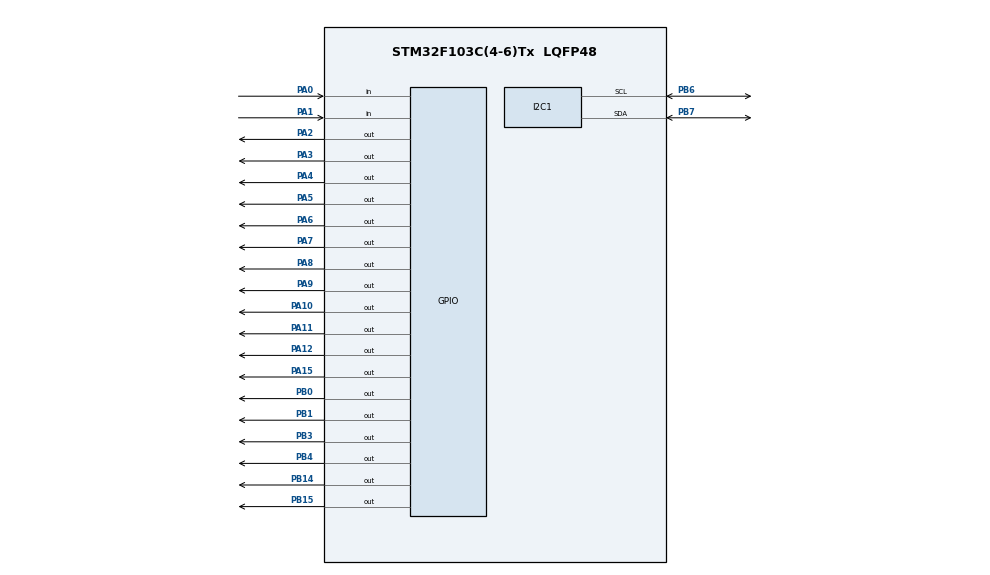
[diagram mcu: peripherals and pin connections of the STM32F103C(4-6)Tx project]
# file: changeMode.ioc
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Mcu.Family=STM32F1
Mcu.Name=STM32F103C(4-6)Tx
Mcu.Package=LQFP48
NVIC.PriorityGroup=NVIC_PRIORITYGROUP_4
PA0-WKUP.GPIO_PuPd=GPIO_PULLUP
PA0-WKUP.Signal=GPIO_Input
PA1.GPIO_PuPd=GPIO_PULLUP
PA1.Signal=GPIO_Input
PA10.Signal=GPIO_Output
PA11.Signal=GPIO_Output
PA12.Signal=GPIO_Output
PA13.Mode=Serial_Wire
PA13.Signal=SYS_JTMS-SWDIO
PA14.Mode=Serial_Wire
PA14.Signal=SYS_JTCK-SWCLK
PA15.Signal=GPIO_Output
PA2.Signal=GPIO_Output
PA3.Signal=GPIO_Output
PA4.Signal=GPIO_Output
PA5.Signal=GPIO_Output
PA6.Signal=GPIO_Output
PA7.Signal=GPIO_Output
PA8.Signal=GPIO_Output
PA9.Signal=GPIO_Output
PB0.Signal=GPIO_Output
PB1.Signal=GPIO_Output
PB14.Signal=GPIO_Output
PB15.Signal=GPIO_Output
PB3.Signal=GPIO_Output
PB4.Signal=GPIO_Output
PB6.Mode=I2C
PB6.Signal=I2C1_SCL
PB7.Mode=I2C
PB7.Signal=I2C1_SDA
PD0-OSC_IN.Mode=HSE-External-Oscillator
PD0-OSC_IN.Signal=RCC_OSC_IN
PD1-OSC_OUT.Mode=HSE-External-Oscillator
PD1-OSC_OUT.Signal=RCC_OSC_OUT
ProjectManager.HeapSize=0x200
ProjectManager.StackSize=0x400
ProjectManager.TargetToolchain=MDK-ARM V5
RCC.APB1Freq_Value=8000000
RCC.APB2Freq_Value=8000000
board=custom

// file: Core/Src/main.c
/* USER CODE BEGIN Header */
/**
  ******************************************************************************
  * @file           : main.c
  * @brief          : Main program body
  ******************************************************************************
  * @attention
  *
  * Copyright (c) 2024 STMicroelectronics.
  * All rights reserved.
  *
  * This software is licensed under terms that can be found in the LICENSE file
  * in the root directory of this software component.
  * If no LICENSE file comes with this software, it is provided AS-IS.
  *
  ******************************************************************************
  */
/* USER CODE END Header */
#include "main.h"
#include "lcd.h"
#include "stdio.h"

I2C_HandleTypeDef hi2c1;

void SystemClock_Config(void);
static void MX_GPIO_Init(void);
static void MX_I2C1_Init(void);

/* USER CODE BEGIN 0 */
void display7Seg(int data);
//void HAL_GPIO_EXTI_Callback(uint16_t GPIO_Pin);
//void show_traffic(uint8_t BacK_Green1, uint8_t BacK_Yellow1,
//	uint8_t BacK_Green2, uint8_t BacK_Yellow2);
//void sleep();
int status;
int counter1;
int counter2;
enum ledColor{
	GREEN,
	YELLOW,
	RED
};
//void sleep(){
////	if(status == 0)
////	{
//	HAL_GPIO_WritePin(GPIOB, GPIO_PIN_15, GPIO_PIN_RESET);
//	HAL_GPIO_WritePin(GPIOB, GPIO_PIN_14, GPIO_PIN_RESET);
//	HAL_GPIO_WritePin(GPIOB, GPIO_PIN_1, GPIO_PIN_RESET);
//	HAL_GPIO_WritePin(GPIOB, GPIO_PIN_0, GPIO_PIN_RESET);
//	while(1){
//
//	//led yellow blink 1HZ
//	HAL_GPIO_WritePin(GPIOA, GPIO_PIN_7, GPIO_PIN_RESET);//R1
//	HAL_GPIO_WritePin(GPIOA, GPIO_PIN_6, GPIO_PIN_RESET);//Y1
//	HAL_GPIO_WritePin(GPIOA, GPIO_PIN_5, GPIO_PIN_RESET);//G1
//	HAL_GPIO_WritePin(GPIOA, GPIO_PIN_4, GPIO_PIN_RESET);//R2
//	HAL_GPIO_WritePin(GPIOA, GPIO_PIN_3, GPIO_PIN_RESET);//Y2
//	HAL_GPIO_WritePin(GPIOA, GPIO_PIN_2, GPIO_PIN_RESET);//G2
//	HAL_Delay(500);
//	HAL_GPIO_WritePin(GPIOA, GPIO_PIN_6, GPIO_PIN_SET);//Y1
//	HAL_GPIO_WritePin(GPIOA, GPIO_PIN_3, GPIO_PIN_SET);//Y2
//	HAL_Delay(500);
//	if(HAL_GPIO_ReadPin(GPIOA, GPIO_PIN_1) == 0){
//		//while(HAL_GPIO_ReadPin(GPIOA, GPIO_PIN_1) == 1);
//		break;
//		status = 0;
//	}

//	}

//}

//void show_traffic(uint8_t BacK_Green1, uint8_t BacK_Yellow1,
//	uint8_t BacK_Green2, uint8_t BacK_Yellow2){
//
//	uint8_t c_Green1 = BacK_Green1;
//	uint8_t c_Yellow1 = BacK_Yellow1;
//	uint8_t c_Red1 = BacK_Green1 + BacK_Yellow1;
//	uint8_t BacK_Red1 = c_Red1;
//	enum ledColor cur_color1 = GREEN;
//
//	uint8_t c_Green2 = BacK_Green2;
//	uint8_t c_Yellow2 = BacK_Yellow2;
//	uint8_t c_Red2 = BacK_Green2 + BacK_Yellow2;
//	uint8_t BacK_Red2 = c_Red2;
//	enum ledColor cur_color2 = RED;
//
//	uint8_t c_1s = BacK_Green1 + BacK_Red2 + 2;
//
//	counter1 = BacK_Green1 - 1;
//	counter2 = BacK_Red2 - 1;
//
//	int sw_led = 0;
//
//	HAL_GPIO_WritePin(GPIOA, GPIO_PIN_7, GPIO_PIN_RESET);//R1
//	HAL_GPIO_WritePin(GPIOA, GPIO_PIN_5, GPIO_PIN_SET);//G1
//	HAL_GPIO_WritePin(GPIOA, GPIO_PIN_6, GPIO_PIN_RESET);//Y1
//
//	HAL_GPIO_WritePin(GPIOA, GPIO_PIN_4, GPIO_PIN_SET);//R2
//	HAL_GPIO_WritePin(GPIOA, GPIO_PIN_2, GPIO_PIN_RESET);//G2
//	HAL_GPIO_WritePin(GPIOA, GPIO_PIN_3, GPIO_PIN_RESET);//Y2
//
////	Lcd_Write_Command(0x80);//write first line 1
////	Lcd_Write_String("Mode:");
////	Lcd_Write_Command(0xC0);//write first line 2
////	Lcd_Write_String("Binh Thuong.");
//
//	while(1){
//		//if(*sleep_mode == 22) break;
//		if(c_Green1 <= 0){
//			HAL_GPIO_WritePin(GPIOA, GPIO_PIN_7, GPIO_PIN_RESET);
//			HAL_GPIO_WritePin(GPIOA, GPIO_PIN_5, GPIO_PIN_RESET);
//			HAL_GPIO_WritePin(GPIOA, GPIO_PIN_6, GPIO_PIN_SET);
//			c_Green1 = BacK_Green1;
//			cur_color1 = YELLOW;
//			counter1 = BacK_Yellow1 - 1;
//		}
//		if(c_Yellow1 <= 0){
//			HAL_GPIO_WritePin(GPIOA, GPIO_PIN_7, GPIO_PIN_SET);
//			HAL_GPIO_WritePin(GPIOA, GPIO_PIN_5, GPIO_PIN_RESET);
//			HAL_GPIO_WritePin(GPIOA, GPIO_PIN_6, GPIO_PIN_RESET);
//			c_Yellow1 = BacK_Yellow1;
//			cur_color1 = RED;
//			counter1 = BacK_Red1 - 1;
//		}

//		if(c_Red1 <= 0){
//			HAL_GPIO_WritePin(GPIOA, GPIO_PIN_7, GPIO_PIN_RESET);
//			HAL_GPIO_WritePin(GPIOA, GPIO_PIN_5, GPIO_PIN_SET);
//			HAL_GPIO_WritePin(GPIOA, GPIO_PIN_6, GPIO_PIN_RESET);
//			c_Red1 = BacK_Green1 + BacK_Yellow1;
//			cur_color1 = GREEN;
//			counter1 = BacK_Green1 - 1;
//		}
//		if(c_Green2 <= 0){
//			HAL_GPIO_WritePin(GPIOA, GPIO_PIN_4, GPIO_PIN_RESET);
//			HAL_GPIO_WritePin(GPIOA, GPIO_PIN_2, GPIO_PIN_RESET);
//			HAL_GPIO_WritePin(GPIOA, GPIO_PIN_3, GPIO_PIN_SET);
//			c_Green2 = BacK_Green2 - 1;
//			cur_color2 = YELLOW;
//			counter2 = BacK_Yellow2 - 1;
//		}
//		if(c_Yellow2 <= 0){
//			HAL_GPIO_WritePin(GPIOA, GPIO_PIN_4, GPIO_PIN_SET);
//			HAL_GPIO_WritePin(GPIOA, GPIO_PIN_2, GPIO_PIN_RESET);
//			HAL_GPIO_WritePin(GPIOA, GPIO_PIN_3, GPIO_PIN_RESET);
//			c_Yellow2 =BacK_Yellow1 - 1;
//			cur_color2 = RED;
//			counter2 = BacK_Red2 - 1;
//		}
//		if(c_Red2 <= 0){
//			HAL_GPIO_WritePin(GPIOA, GPIO_PIN_4, GPIO_PIN_RESET);
//			HAL_GPIO_WritePin(GPIOA, GPIO_PIN_2, GPIO_PIN_SET);
//			HAL_GPIO_WritePin(GPIOA, GPIO_PIN_3, GPIO_PIN_RESET);
//			c_Red2 = BacK_Green2 + BacK_Yellow2;
//			cur_color2 = GREEN;
//			counter2 = BacK_Green2 - 1;
//		}
//		if(c_1s <= 0){
//			switch(cur_color1){
//				case GREEN:
//						c_Green1--;
//						break;
//				case YELLOW:
//						c_Yellow1--;
//						break;
//				case RED:
//						c_Red1--;
//						break;
//			}
//			switch(cur_color2){
//				case GREEN:
//						c_Green2--;
//						break;
//				case YELLOW:
//						c_Yellow2--;
//						break;
//				case RED:
//						c_Red2--;
//						break;
//			}
//			counter1--;
//			counter2--;
//			c_1s = BacK_Green1 + BacK_Red2 + 2;
//		}
//		switch(sw_led){
//			case 0:
//				HAL_GPIO_WritePin(GPIOB, GPIO_PIN_15, GPIO_PIN_RESET);//EN3
//				HAL_GPIO_WritePin(GPIOB, GPIO_PIN_0, GPIO_PIN_SET);//EN0
//				display7Seg(counter1/10);
//				sw_led = 1;
//				break;
//			case 1:
//				HAL_GPIO_WritePin(GPIOB, GPIO_PIN_0, GPIO_PIN_RESET);//EN0
//				HAL_GPIO_WritePin(GPIOB, GPIO_PIN_1, GPIO_PIN_SET);//EN1
//				display7Seg(counter1%10);
//				sw_led = 2;
//				break;
//			case 2:
//				HAL_GPIO_WritePin(GPIOB, GPIO_PIN_1, GPIO_PIN_RESET);//EN1
//				HAL_GPIO_WritePin(GPIOB, GPIO_PIN_14, GPIO_PIN_SET);//EN2
//				display7Seg(counter2/10);
//				sw_led = 3;
//				break;
//			case 3:
//				HAL_GPIO_WritePin(GPIOB, GPIO_PIN_14, GPIO_PIN_RESET);//EN2
//				HAL_GPIO_WritePin(GPIOB, GPIO_PIN_15, GPIO_PIN_SET);//EN3
//				display7Seg(counter2%10);
//				sw_led = 0;
//				break;
//		}
//		c_1s--;
//		HAL_Delay(10);
//		if(HAL_GPIO_ReadPin(GPIOA, GPIO_PIN_0) == 0){
//			//while(HAL_GPIO_ReadPin(GPIOA, GPIO_PIN_0) == 1);
//			break;
//			status = 1;
//		}
//		if(HAL_GPIO_ReadPin(GPIOA, GPIO_PIN_1) == 0){
//			//while(HAL_GPIO_ReadPin(GPIOA, GPIO_PIN_1) == 1);
//			break;
//		}
//		}
//
//}
/* USER CODE END 0 */

int main(void)
{

  /* MCU Configuration--------------------------------------------------------*/

  /* Reset of all peripherals, Initializes the Flash interface and the Systick. */
  HAL_Init();

  /* Configure the system clock */
  SystemClock_Config();

  /* Initialize all configured peripherals */
  MX_GPIO_Init();
  MX_I2C1_Init();
  /* USER CODE BEGIN 2 */
	lcd_init();
	status = 0;
	lcd_put_cur(0, 0);
		lcd_send_string("Mode: Normal              ");
		//HAL_Delay(10);
		lcd_put_cur(1, 0);
		lcd_send_string("R:28s G:24s Y:4s          ");
		uint8_t c_Green1 = 24;
		uint8_t c_Yellow1 = 4;
		uint8_t c_Red1 = 28;
//		uint8_t BacK_Red1 = c_Red1;
		enum ledColor cur_color1 = GREEN;

		uint8_t c_Green2 = 22;
		uint8_t c_Yellow2 = 4;
		uint8_t c_Red2 = 26;
//		uint8_t BacK_Red2 = c_Red2;
		enum ledColor cur_color2 = RED;

		uint8_t c_1s = 50;

		counter1 = 21;
		counter2 = 25;

		int sw_led = 0;

		HAL_GPIO_WritePin(GPIOA, GPIO_PIN_7, GPIO_PIN_RESET);//R1
		HAL_GPIO_WritePin(GPIOA, GPIO_PIN_5, GPIO_PIN_SET);//G1
		HAL_GPIO_WritePin(GPIOA, GPIO_PIN_6, GPIO_PIN_RESET);//Y1

		HAL_GPIO_WritePin(GPIOA, GPIO_PIN_4, GPIO_PIN_SET);//R2
		HAL_GPIO_WritePin(GPIOA, GPIO_PIN_2, GPIO_PIN_RESET);//G2
		HAL_GPIO_WritePin(GPIOA, GPIO_PIN_3, GPIO_PIN_RESET);//Y2
//	lcd_put_cur(0, 0);
//		lcd_send_string("Mode: Normal              ");
//		//HAL_Delay(10);
//		lcd_put_cur(1, 0);
//		lcd_send_string("R:26s G:22s Y:4s          ");
//		show_traffic(22, 4, 22, 4);
//		if(HAL_GPIO_ReadPin(GPIOA, GPIO_PIN_0) == 0){
//			while(HAL_GPIO_ReadPin(GPIOA, GPIO_PIN_0) == 0);
//			lcd_put_cur(0, 0);
//			lcd_send_string("Mode: Sleep                ");
//			//HAL_Delay(10);
//			lcd_put_cur(1, 0);
//			lcd_send_string("Yellow blink 1HZ             ");
//			sleep();
//		}
//		if(HAL_GPIO_ReadPin(GPIOA, GPIO_PIN_1) == 0){
//			while(HAL_GPIO_ReadPin(GPIOA, GPIO_PIN_1) == 0);
//			lcd_put_cur(0, 0);
//			lcd_send_string("Mode: Rush                ");
//			//HAL_Delay(10);
//			lcd_put_cur(1, 0);
//			lcd_send_string("R:32s G:28s Y:4s              ");
//			show_traffic(28, 4, 28, 4);
//		}
  /* Infinite loop */
  /* USER CODE BEGIN WHILE */
  while (1)
  {

		//if(*sleep_mode == 22) break;
		if(c_Green1 <= 0){
			HAL_GPIO_WritePin(GPIOA, GPIO_PIN_7, GPIO_PIN_RESET);
			HAL_GPIO_WritePin(GPIOA, GPIO_PIN_5, GPIO_PIN_RESET);
			HAL_GPIO_WritePin(GPIOA, GPIO_PIN_6, GPIO_PIN_SET);
			c_Green1 = 22;
			cur_color1 = YELLOW;
			counter1 = 3;
		}
		if(c_Yellow1 <= 0){
			HAL_GPIO_WritePin(GPIOA, GPIO_PIN_7, GPIO_PIN_SET);
			HAL_GPIO_WritePin(GPIOA, GPIO_PIN_5, GPIO_PIN_RESET);
			HAL_GPIO_WritePin(GPIOA, GPIO_PIN_6, GPIO_PIN_RESET);
			c_Yellow1 = 4;
			cur_color1 = RED;
			counter1 = 25;
		}

		if(c_Red1 <= 0){
			HAL_GPIO_WritePin(GPIOA, GPIO_PIN_7, GPIO_PIN_RESET);
			HAL_GPIO_WritePin(GPIOA, GPIO_PIN_5, GPIO_PIN_SET);
			HAL_GPIO_WritePin(GPIOA, GPIO_PIN_6, GPIO_PIN_RESET);
			c_Red1 = 26;
			cur_color1 = GREEN;
			counter1 = 21;
		}
		if(c_Green2 <= 0){
			HAL_GPIO_WritePin(GPIOA, GPIO_PIN_4, GPIO_PIN_RESET);
			HAL_GPIO_WritePin(GPIOA, GPIO_PIN_2, GPIO_PIN_RESET);
			HAL_GPIO_WritePin(GPIOA, GPIO_PIN_3, GPIO_PIN_SET);
			c_Green2 = 21;
			cur_color2 = YELLOW;
			counter2 = 3;
		}
		if(c_Yellow2 <= 0){
			HAL_GPIO_WritePin(GPIOA, GPIO_PIN_4, GPIO_PIN_SET);
			HAL_GPIO_WritePin(GPIOA, GPIO_PIN_2, GPIO_PIN_RESET);
			HAL_GPIO_WritePin(GPIOA, GPIO_PIN_3, GPIO_PIN_RESET);
			c_Yellow2 = 3;
			cur_color2 = RED;
			counter2 = 25;
		}
		if(c_Red2 <= 0){
			HAL_GPIO_WritePin(GPIOA, GPIO_PIN_4, GPIO_PIN_RESET);
			HAL_GPIO_WritePin(GPIOA, GPIO_PIN_2, GPIO_PIN_SET);
			HAL_GPIO_WritePin(GPIOA, GPIO_PIN_3, GPIO_PIN_RESET);
			c_Red2 = 25;
			cur_color2 = GREEN;
			counter2 = 21;
		}
		if(c_1s <= 0){
			switch(cur_color1){
				case GREEN:
						c_Green1--;
						break;
				case YELLOW:
						c_Yellow1--;
						break;
				case RED:
						c_Red1--;
						break;
			}
			switch(cur_color2){
				case GREEN:
						c_Green2--;
						break;
				case YELLOW:
						c_Yellow2--;
						break;
				case RED:
						c_Red2--;
						break;
			}
			counter1--;
			counter2--;
			c_1s = 50;
		}
		switch(sw_led){
			case 0:
				HAL_GPIO_WritePin(GPIOB, GPIO_PIN_15, GPIO_PIN_RESET);//EN3
				HAL_GPIO_WritePin(GPIOB, GPIO_PIN_0, GPIO_PIN_SET);//EN0
				display7Seg(counter1/10);
				sw_led = 1;
				break;
			case 1:
				HAL_GPIO_WritePin(GPIOB, GPIO_PIN_0, GPIO_PIN_RESET);//EN0
				HAL_GPIO_WritePin(GPIOB, GPIO_PIN_1, GPIO_PIN_SET);//EN1
				display7Seg(counter1%10);
				sw_led = 2;
				break;
			case 2:
				HAL_GPIO_WritePin(GPIOB, GPIO_PIN_1, GPIO_PIN_RESET);//EN1
				HAL_GPIO_WritePin(GPIOB, GPIO_PIN_14, GPIO_PIN_SET);//EN2
				display7Seg(counter2/10);
				sw_led = 3;
				break;
			case 3:
				HAL_GPIO_WritePin(GPIOB, GPIO_PIN_14, GPIO_PIN_RESET);//EN2
				HAL_GPIO_WritePin(GPIOB, GPIO_PIN_15, GPIO_PIN_SET);//EN3
				display7Seg(counter2%10);
				sw_led = 0;
				break;
		}
		c_1s--;
		HAL_Delay(10);
		if(HAL_GPIO_ReadPin(GPIOA, GPIO_PIN_0) == 1){
			while(HAL_GPIO_ReadPin(GPIOA, GPIO_PIN_0) == 1);
			break;
		}
	}
		if(HAL_GPIO_ReadPin(GPIOA, GPIO_PIN_0) == 1){
			while(HAL_GPIO_ReadPin(GPIOA, GPIO_PIN_0) == 1);
			HAL_GPIO_WritePin(GPIOB, GPIO_PIN_15, GPIO_PIN_RESET);
			HAL_GPIO_WritePin(GPIOB, GPIO_PIN_14, GPIO_PIN_RESET);
			HAL_GPIO_WritePin(GPIOB, GPIO_PIN_1, GPIO_PIN_RESET);
			HAL_GPIO_WritePin(GPIOB, GPIO_PIN_0, GPIO_PIN_RESET);
			while(1){
					//led yellow blink 1HZ
				HAL_GPIO_WritePin(GPIOA, GPIO_PIN_7, GPIO_PIN_RESET);//R1
				HAL_GPIO_WritePin(GPIOA, GPIO_PIN_6, GPIO_PIN_RESET);//Y1
				HAL_GPIO_WritePin(GPIOA, GPIO_PIN_5, GPIO_PIN_RESET);//G1
				HAL_GPIO_WritePin(GPIOA, GPIO_PIN_4, GPIO_PIN_RESET);//R2
				HAL_GPIO_WritePin(GPIOA, GPIO_PIN_3, GPIO_PIN_RESET);//Y2
				HAL_GPIO_WritePin(GPIOA, GPIO_PIN_2, GPIO_PIN_RESET);//G2
				HAL_Delay(500);
				HAL_GPIO_WritePin(GPIOA, GPIO_PIN_6, GPIO_PIN_SET);//Y1
				HAL_GPIO_WritePin(GPIOA, GPIO_PIN_3, GPIO_PIN_SET);//Y2
				HAL_Delay(500);
				if(HAL_GPIO_ReadPin(GPIOA, GPIO_PIN_1) == 1){
					//while(HAL_GPIO_ReadPin(GPIOA, GPIO_PIN_1) == 1);
					break;
					status = 0;
				}

	}
		}
	}

void display7Seg(int data){
	switch (data)
	{
		case 0:
			HAL_GPIO_WritePin(GPIOA, GPIO_PIN_8, GPIO_PIN_RESET);
			HAL_GPIO_WritePin(GPIOA, GPIO_PIN_9, GPIO_PIN_RESET);
			HAL_GPIO_WritePin(GPIOA, GPIO_PIN_10, GPIO_PIN_RESET);
			HAL_GPIO_WritePin(GPIOA, GPIO_PIN_11, GPIO_PIN_RESET);
			HAL_GPIO_WritePin(GPIOA, GPIO_PIN_12, GPIO_PIN_RESET);
			HAL_GPIO_WritePin(GPIOA, GPIO_PIN_15, GPIO_PIN_RESET);
			HAL_GPIO_WritePin(GPIOB, GPIO_PIN_3, GPIO_PIN_SET);
			HAL_GPIO_WritePin(GPIOB, GPIO_PIN_4, GPIO_PIN_SET);
			break;
		case 1:
			HAL_GPIO_WritePin(GPIOA, GPIO_PIN_8, GPIO_PIN_SET);
			HAL_GPIO_WritePin(GPIOA, GPIO_PIN_9, GPIO_PIN_RESET);
			HAL_GPIO_WritePin(GPIOA, GPIO_PIN_10, GPIO_PIN_RESET);
			HAL_GPIO_WritePin(GPIOA, GPIO_PIN_11, GPIO_PIN_SET);
			HAL_GPIO_WritePin(GPIOA, GPIO_PIN_12, GPIO_PIN_SET);
			HAL_GPIO_WritePin(GPIOA, GPIO_PIN_15, GPIO_PIN_SET);
			HAL_GPIO_WritePin(GPIOB, GPIO_PIN_3, GPIO_PIN_SET);
			HAL_GPIO_WritePin(GPIOB, GPIO_PIN_4, GPIO_PIN_SET);
			break;
		case 2:
			HAL_GPIO_WritePin(GPIOA, GPIO_PIN_8, GPIO_PIN_RESET);
			HAL_GPIO_WritePin(GPIOA, GPIO_PIN_9, GPIO_PIN_RESET);
			HAL_GPIO_WritePin(GPIOA, GPIO_PIN_10, GPIO_PIN_SET);
			HAL_GPIO_WritePin(GPIOA, GPIO_PIN_11, GPIO_PIN_RESET);
			HAL_GPIO_WritePin(GPIOA, GPIO_PIN_12, GPIO_PIN_RESET);
			HAL_GPIO_WritePin(GPIOA, GPIO_PIN_15, GPIO_PIN_SET);
			HAL_GPIO_WritePin(GPIOB, GPIO_PIN_3, GPIO_PIN_RESET);
			HAL_GPIO_WritePin(GPIOB, GPIO_PIN_4, GPIO_PIN_SET);
			break;
		case 3:
			HAL_GPIO_WritePin(GPIOA, GPIO_PIN_8, GPIO_PIN_RESET);
			HAL_GPIO_WritePin(GPIOA, GPIO_PIN_9, GPIO_PIN_RESET);
			HAL_GPIO_WritePin(GPIOA, GPIO_PIN_10, GPIO_PIN_RESET);
			HAL_GPIO_WritePin(GPIOA, GPIO_PIN_11, GPIO_PIN_RESET);
			HAL_GPIO_WritePin(GPIOA, GPIO_PIN_12, GPIO_PIN_SET);
			HAL_GPIO_WritePin(GPIOA, GPIO_PIN_15, GPIO_PIN_SET);
			HAL_GPIO_WritePin(GPIOB, GPIO_PIN_3, GPIO_PIN_RESET);
		  HAL_GPIO_WritePin(GPIOB, GPIO_PIN_4, GPIO_PIN_SET);
			break;
		case 4:
			HAL_GPIO_WritePin(GPIOA, GPIO_PIN_8, GPIO_PIN_SET);
			HAL_GPIO_WritePin(GPIOA, GPIO_PIN_9, GPIO_PIN_RESET);
			HAL_GPIO_WritePin(GPIOA, GPIO_PIN_10, GPIO_PIN_RESET);
			HAL_GPIO_WritePin(GPIOA, GPIO_PIN_11, GPIO_PIN_SET);
			HAL_GPIO_WritePin(GPIOA, GPIO_PIN_12, GPIO_PIN_SET);
			HAL_GPIO_WritePin(GPIOA, GPIO_PIN_15, GPIO_PIN_RESET);
			HAL_GPIO_WritePin(GPIOB, GPIO_PIN_3, GPIO_PIN_RESET);
			HAL_GPIO_WritePin(GPIOB, GPIO_PIN_4, GPIO_PIN_SET);
			break;
		case 5:
			HAL_GPIO_WritePin(GPIOA, GPIO_PIN_8, GPIO_PIN_RESET);
			HAL_GPIO_WritePin(GPIOA, GPIO_PIN_9, GPIO_PIN_SET);
			HAL_GPIO_WritePin(GPIOA, GPIO_PIN_10, GPIO_PIN_RESET);
			HAL_GPIO_WritePin(GPIOA, GPIO_PIN_11, GPIO_PIN_RESET);
			HAL_GPIO_WritePin(GPIOA, GPIO_PIN_12, GPIO_PIN_SET);
			HAL_GPIO_WritePin(GPIOA, GPIO_PIN_15, GPIO_PIN_RESET);
			HAL_GPIO_WritePin(GPIOB, GPIO_PIN_3, GPIO_PIN_RESET);
			HAL_GPIO_WritePin(GPIOB, GPIO_PIN_4, GPIO_PIN_SET);
			break;
		case 6:
			HAL_GPIO_WritePin(GPIOA, GPIO_PIN_8, GPIO_PIN_RESET);
			HAL_GPIO_WritePin(GPIOA, GPIO_PIN_9, GPIO_PIN_SET);
			HAL_GPIO_WritePin(GPIOA, GPIO_PIN_10, GPIO_PIN_RESET);
			HAL_GPIO_WritePin(GPIOA, GPIO_PIN_11, GPIO_PIN_RESET);
			HAL_GPIO_WritePin(GPIOA, GPIO_PIN_12, GPIO_PIN_RESET);
			HAL_GPIO_WritePin(GPIOA, GPIO_PIN_15, GPIO_PIN_RESET);
			HAL_GPIO_WritePin(GPIOB, GPIO_PIN_3, GPIO_PIN_RESET);
			HAL_GPIO_WritePin(GPIOB, GPIO_PIN_4, GPIO_PIN_SET);
			break;
	 case 7:
			HAL_GPIO_WritePin(GPIOA, GPIO_PIN_8, GPIO_PIN_RESET);
			HAL_GPIO_WritePin(GPIOA, GPIO_PIN_9, GPIO_PIN_RESET);
			HAL_GPIO_WritePin(GPIOA, GPIO_PIN_10, GPIO_PIN_RESET);
			HAL_GPIO_WritePin(GPIOA, GPIO_PIN_11, GPIO_PIN_SET);
			HAL_GPIO_WritePin(GPIOA, GPIO_PIN_12, GPIO_PIN_SET);
			HAL_GPIO_WritePin(GPIOA, GPIO_PIN_15, GPIO_PIN_SET);
			HAL_GPIO_WritePin(GPIOB, GPIO_PIN_3, GPIO_PIN_SET);
			HAL_GPIO_WritePin(GPIOB, GPIO_PIN_4, GPIO_PIN_SET);
			break;
		case 8:
			HAL_GPIO_WritePin(GPIOA, GPIO_PIN_8, GPIO_PIN_RESET);
			HAL_GPIO_WritePin(GPIOA, GPIO_PIN_9, GPIO_PIN_RESET);
			HAL_GPIO_WritePin(GPIOA, GPIO_PIN_10, GPIO_PIN_RESET);
			HAL_GPIO_WritePin(GPIOA, GPIO_PIN_11, GPIO_PIN_RESET);
			HAL_GPIO_WritePin(GPIOA, GPIO_PIN_12, GPIO_PIN_RESET);
			HAL_GPIO_WritePin(GPIOA, GPIO_PIN_15, GPIO_PIN_RESET);
			HAL_GPIO_WritePin(GPIOB, GPIO_PIN_3, GPIO_PIN_RESET);
			HAL_GPIO_WritePin(GPIOB, GPIO_PIN_4, GPIO_PIN_SET);
			break;
		case 9:
			HAL_GPIO_WritePin(GPIOA, GPIO_PIN_8, GPIO_PIN_RESET);
			HAL_GPIO_WritePin(GPIOA, GPIO_PIN_9, GPIO_PIN_RESET);
			HAL_GPIO_WritePin(GPIOA, GPIO_PIN_10, GPIO_PIN_RESET);
			HAL_GPIO_WritePin(GPIOA, GPIO_PIN_11, GPIO_PIN_RESET);
			HAL_GPIO_WritePin(GPIOA, GPIO_PIN_12, GPIO_PIN_SET);
			HAL_GPIO_WritePin(GPIOA, GPIO_PIN_15, GPIO_PIN_RESET);
			HAL_GPIO_WritePin(GPIOB, GPIO_PIN_3, GPIO_PIN_RESET);
			HAL_GPIO_WritePin(GPIOB, GPIO_PIN_4, GPIO_PIN_SET);
			break;
	}
}
void SystemClock_Config(void)
{
  RCC_OscInitTypeDef RCC_OscInitStruct = {0};
  RCC_ClkInitTypeDef RCC_ClkInitStruct = {0};

  /** Initializes the RCC Oscillators according to the specified parameters
  * in the RCC_OscInitTypeDef structure.
  */
  RCC_OscInitStruct.OscillatorType = RCC_OSCILLATORTYPE_HSI;
  RCC_OscInitStruct.HSIState = RCC_HSI_ON;
  RCC_OscInitStruct.HSICalibrationValue = RCC_HSICALIBRATION_DEFAULT;
  RCC_OscInitStruct.PLL.PLLState = RCC_PLL_NONE;
  if (HAL_RCC_OscConfig(&RCC_OscInitStruct) != HAL_OK)
  {
    Error_Handler();
  }

  /** Initializes the CPU, AHB and APB buses clocks
  */
  RCC_ClkInitStruct.ClockType = RCC_CLOCKTYPE_HCLK|RCC_CLOCKTYPE_SYSCLK
                              |RCC_CLOCKTYPE_PCLK1|RCC_CLOCKTYPE_PCLK2;
  RCC_ClkInitStruct.SYSCLKSource = RCC_SYSCLKSOURCE_HSI;
  RCC_ClkInitStruct.AHBCLKDivider = RCC_SYSCLK_DIV1;
  RCC_ClkInitStruct.APB1CLKDivider = RCC_HCLK_DIV1;
  RCC_ClkInitStruct.APB2CLKDivider = RCC_HCLK_DIV1;

  if (HAL_RCC_ClockConfig(&RCC_ClkInitStruct, FLASH_LATENCY_0) != HAL_OK)
  {
    Error_Handler();
  }
}

static void MX_I2C1_Init(void)
{

  hi2c1.Instance = I2C1;
  hi2c1.Init.ClockSpeed = 100000;
  hi2c1.Init.DutyCycle = I2C_DUTYCYCLE_2;
  hi2c1.Init.OwnAddress1 = 0;
  hi2c1.Init.AddressingMode = I2C_ADDRESSINGMODE_7BIT;
  hi2c1.Init.DualAddressMode = I2C_DUALADDRESS_DISABLE;
  hi2c1.Init.OwnAddress2 = 0;
  hi2c1.Init.GeneralCallMode = I2C_GENERALCALL_DISABLE;
  hi2c1.Init.NoStretchMode = I2C_NOSTRETCH_DISABLE;
  if (HAL_I2C_Init(&hi2c1) != HAL_OK)
  {
    Error_Handler();
  }

}

static void MX_GPIO_Init(void)
{
  GPIO_InitTypeDef GPIO_InitStruct = {0};

  /* GPIO Ports Clock Enable */
  __HAL_RCC_GPIOD_CLK_ENABLE();
  __HAL_RCC_GPIOA_CLK_ENABLE();
  __HAL_RCC_GPIOB_CLK_ENABLE();

  /*Configure GPIO pin Output Level */
  HAL_GPIO_WritePin(GPIOA, GPIO_PIN_2|GPIO_PIN_3|GPIO_PIN_4|GPIO_PIN_5
                          |GPIO_PIN_6|GPIO_PIN_7|GPIO_PIN_8|GPIO_PIN_9
                          |GPIO_PIN_10|GPIO_PIN_11|GPIO_PIN_12|GPIO_PIN_15, GPIO_PIN_RESET);

  /*Configure GPIO pin Output Level */
  HAL_GPIO_WritePin(GPIOB, GPIO_PIN_0|GPIO_PIN_1|GPIO_PIN_14|GPIO_PIN_15
                          |GPIO_PIN_3|GPIO_PIN_4, GPIO_PIN_RESET);

  /*Configure GPIO pins : PA0 PA1 */
  GPIO_InitStruct.Pin = GPIO_PIN_0|GPIO_PIN_1;
  GPIO_InitStruct.Mode = GPIO_MODE_INPUT;
  GPIO_InitStruct.Pull = GPIO_PULLUP;
  HAL_GPIO_Init(GPIOA, &GPIO_InitStruct);

  /*Configure GPIO pins : PA2 PA3 PA4 PA5
                           PA6 PA7 PA8 PA9
                           PA10 PA11 PA12 PA15 */
  GPIO_InitStruct.Pin = GPIO_PIN_2|GPIO_PIN_3|GPIO_PIN_4|GPIO_PIN_5
                          |GPIO_PIN_6|GPIO_PIN_7|GPIO_PIN_8|GPIO_PIN_9
                          |GPIO_PIN_10|GPIO_PIN_11|GPIO_PIN_12|GPIO_PIN_15;
  GPIO_InitStruct.Mode = GPIO_MODE_OUTPUT_PP;
  GPIO_InitStruct.Pull = GPIO_NOPULL;
  GPIO_InitStruct.Speed = GPIO_SPEED_FREQ_LOW;
  HAL_GPIO_Init(GPIOA, &GPIO_InitStruct);

  /*Configure GPIO pins : PB0 PB1 PB14 PB15
                           PB3 PB4 */
  GPIO_InitStruct.Pin = GPIO_PIN_0|GPIO_PIN_1|GPIO_PIN_14|GPIO_PIN_15
                          |GPIO_PIN_3|GPIO_PIN_4;
  GPIO_InitStruct.Mode = GPIO_MODE_OUTPUT_PP;
  GPIO_InitStruct.Pull = GPIO_NOPULL;
  GPIO_InitStruct.Speed = GPIO_SPEED_FREQ_LOW;
  HAL_GPIO_Init(GPIOB, &GPIO_InitStruct);

}

void Error_Handler(void)
{
  __disable_irq();
  while (1)
  {
  }
}
